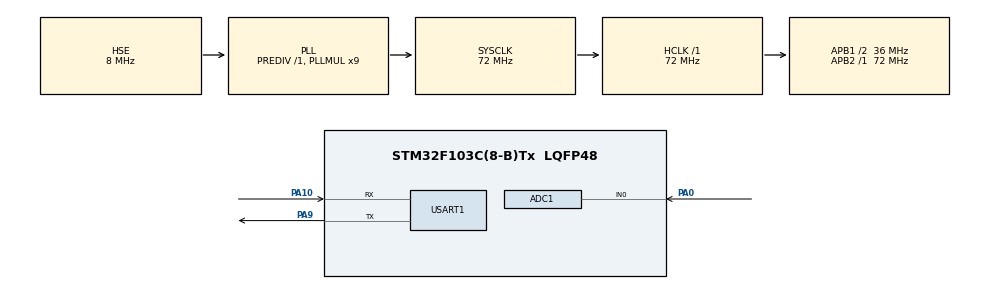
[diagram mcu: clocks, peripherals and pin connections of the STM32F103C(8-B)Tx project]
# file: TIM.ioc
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ADC1.Channel-0\#ChannelRegularConversion=ADC_CHANNEL_0
ADC1.NbrOfConversionFlag=1
ADC1.Rank-0\#ChannelRegularConversion=1
ADC1.SamplingTime-0\#ChannelRegularConversion=ADC_SAMPLETIME_1CYCLE_5
ADC1.master=1
Mcu.Family=STM32F1
Mcu.Name=STM32F103C(8-B)Tx
Mcu.Package=LQFP48
NVIC.PriorityGroup=NVIC_PRIORITYGROUP_4
NVIC.TIM4_IRQn=true\:0\:0\:false\:false\:true\:true\:true\:true
NVIC.USART1_IRQn=true\:0\:0\:false\:false\:true\:true\:true\:true
PA0-WKUP.Signal=ADCx_IN0
PA10.Mode=Asynchronous
PA10.Signal=USART1_RX
PA13.Mode=Serial_Wire
PA13.Signal=SYS_JTMS-SWDIO
PA14.Mode=Serial_Wire
PA14.Signal=SYS_JTCK-SWCLK
PA9.Mode=Asynchronous
PA9.Signal=USART1_TX
PD0-OSC_IN.Mode=HSE-External-Oscillator
PD0-OSC_IN.Signal=RCC_OSC_IN
PD1-OSC_OUT.Mode=HSE-External-Oscillator
PD1-OSC_OUT.Signal=RCC_OSC_OUT
ProjectManager.HeapSize=0x200
ProjectManager.StackSize=0x400
ProjectManager.TargetToolchain=CMake
RCC.ADCPresc=RCC_ADCPCLK2_DIV6
RCC.AHBFreq_Value=72000000
RCC.APB1CLKDivider=RCC_HCLK_DIV2
RCC.APB1Freq_Value=36000000
RCC.APB1TimFreq_Value=72000000
RCC.APB2Freq_Value=72000000
RCC.APB2TimFreq_Value=72000000
RCC.HCLKFreq_Value=72000000
RCC.PLLMUL=RCC_PLL_MUL9
RCC.PLLSourceVirtual=RCC_PLLSOURCE_HSE
RCC.SYSCLKFreq_VALUE=72000000
RCC.SYSCLKSource=RCC_SYSCLKSOURCE_PLLCLK
RCC.USBFreq_Value=72000000
SH.ADCx_IN0.0=ADC1_IN0,IN0
TIM4.Prescaler=7199
USART1.VirtualMode=VM_ASYNC
VP_TIM4_VS_ClockSourceINT.Mode=Internal
board=custom

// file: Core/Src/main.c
/* USER CODE BEGIN Header */
/**
  ******************************************************************************
  * @file           : main.c
  * @brief          : Main program body
  ******************************************************************************
  * @attention
  *
  * Copyright (c) 2026 STMicroelectronics.
  * All rights reserved.
  *
  * This software is licensed under terms that can be found in the LICENSE file
  * in the root directory of this software component.
  * If no LICENSE file comes with this software, it is provided AS-IS.
  *
  ******************************************************************************
  */
/* USER CODE END Header */
#include "main.h"

/* USER CODE BEGIN Includes */
#include <stdio.h>
#include <string.h>
/* USER CODE END Includes */

ADC_HandleTypeDef hadc1;

TIM_HandleTypeDef htim4;

UART_HandleTypeDef huart1;

/* USER CODE BEGIN PV */
/* TIM4 当前配置：Prescaler=7199 → 10 kHz，一个计数 = 0.1 ms */
uint32_t tim_total_01ms = 0U;   /* 累计的 0.1ms 计数 */
uint16_t tim_last_cnt   = 0U;   /* 上一次读到的 CNT，用于算增量 */
/* USER CODE END PV */

void SystemClock_Config(void);
static void MX_GPIO_Init(void);
static void MX_ADC1_Init(void);
static void MX_USART1_UART_Init(void);
static void MX_TIM4_Init(void);

/* USER CODE BEGIN 0 */
/**
  * @brief  把 TIM4 的计数增量累加进 tim_total_01ms
  * @note   CNT 是 16 位的，65535 之后回到 0。用无符号相减
  *         (uint16_t)(now - last) 天然就能跨过一次回绕算对增量，
  *         不需要手动判断"是不是变小了"。
  */
static void tim_update(void)
{
  uint16_t now   = (uint16_t)__HAL_TIM_GET_COUNTER(&htim4);
  uint16_t delta = (uint16_t)(now - tim_last_cnt);

  tim_last_cnt   = now;
  tim_total_01ms += delta;
}
/* USER CODE END 0 */

int main(void)
{

  /* MCU Configuration--------------------------------------------------------*/

  /* Reset of all peripherals, Initializes the Flash interface and the Systick. */
  HAL_Init();

  /* Configure the system clock */
  SystemClock_Config();

  /* Initialize all configured peripherals */
  MX_GPIO_Init();
  MX_ADC1_Init();
  MX_USART1_UART_Init();
  MX_TIM4_Init();
  /* USER CODE BEGIN 2 */
  static char msg[48];
  const char *boot = "TIM4 timer started\r\n";
  uint32_t last_print = 0U;

  HAL_TIM_Base_Start(&htim4);                    /* 启动 TIM4 开始计数 */
  tim_last_cnt   = (uint16_t)__HAL_TIM_GET_COUNTER(&htim4);
  tim_total_01ms = 0U;

  HAL_UART_Transmit(&huart1, (uint8_t *)boot, (uint16_t)strlen(boot), 200U);
  /* USER CODE END 2 */

  /* Infinite loop */
  /* USER CODE BEGIN WHILE */
  while (1)
  {
    uint16_t cnt;
    uint32_t ms;

    tim_update();                     /* 每圈都更新，快速转圈不会漏掉回绕 */

    if ((HAL_GetTick() - last_print) >= 100U)
    {
      last_print = HAL_GetTick();

      cnt = (uint16_t)__HAL_TIM_GET_COUNTER(&htim4);
      ms  = tim_total_01ms / 10U;     /* 0.1ms 计数换算成毫秒 */

      sprintf(msg, "CNT=%5u  elapsed=%lu ms\r\n", (unsigned)cnt, (unsigned long)ms);
      HAL_UART_Transmit(&huart1, (uint8_t *)msg, (uint16_t)strlen(msg), 200U);
    }
    /* USER CODE END WHILE */

  }
}

void SystemClock_Config(void)
{
  RCC_OscInitTypeDef RCC_OscInitStruct = {0};
  RCC_ClkInitTypeDef RCC_ClkInitStruct = {0};
  RCC_PeriphCLKInitTypeDef PeriphClkInit = {0};

  /** Initializes the RCC Oscillators according to the specified parameters
  * in the RCC_OscInitTypeDef structure.
  */
  RCC_OscInitStruct.OscillatorType = RCC_OSCILLATORTYPE_HSE;
  RCC_OscInitStruct.HSEState = RCC_HSE_ON;
  RCC_OscInitStruct.HSEPredivValue = RCC_HSE_PREDIV_DIV1;
  RCC_OscInitStruct.HSIState = RCC_HSI_ON;
  RCC_OscInitStruct.PLL.PLLState = RCC_PLL_ON;
  RCC_OscInitStruct.PLL.PLLSource = RCC_PLLSOURCE_HSE;
  RCC_OscInitStruct.PLL.PLLMUL = RCC_PLL_MUL9;
  if (HAL_RCC_OscConfig(&RCC_OscInitStruct) != HAL_OK)
  {
    Error_Handler();
  }

  /** Initializes the CPU, AHB and APB buses clocks
  */
  RCC_ClkInitStruct.ClockType = RCC_CLOCKTYPE_HCLK|RCC_CLOCKTYPE_SYSCLK
                              |RCC_CLOCKTYPE_PCLK1|RCC_CLOCKTYPE_PCLK2;
  RCC_ClkInitStruct.SYSCLKSource = RCC_SYSCLKSOURCE_PLLCLK;
  RCC_ClkInitStruct.AHBCLKDivider = RCC_SYSCLK_DIV1;
  RCC_ClkInitStruct.APB1CLKDivider = RCC_HCLK_DIV2;
  RCC_ClkInitStruct.APB2CLKDivider = RCC_HCLK_DIV1;

  if (HAL_RCC_ClockConfig(&RCC_ClkInitStruct, FLASH_LATENCY_2) != HAL_OK)
  {
    Error_Handler();
  }
  PeriphClkInit.PeriphClockSelection = RCC_PERIPHCLK_ADC;
  PeriphClkInit.AdcClockSelection = RCC_ADCPCLK2_DIV6;
  if (HAL_RCCEx_PeriphCLKConfig(&PeriphClkInit) != HAL_OK)
  {
    Error_Handler();
  }
}

static void MX_ADC1_Init(void)
{

  ADC_ChannelConfTypeDef sConfig = {0};

  /** Common config
  */
  hadc1.Instance = ADC1;
  hadc1.Init.ScanConvMode = ADC_SCAN_DISABLE;
  hadc1.Init.ContinuousConvMode = DISABLE;
  hadc1.Init.DiscontinuousConvMode = DISABLE;
  hadc1.Init.ExternalTrigConv = ADC_SOFTWARE_START;
  hadc1.Init.DataAlign = ADC_DATAALIGN_RIGHT;
  hadc1.Init.NbrOfConversion = 1;
  if (HAL_ADC_Init(&hadc1) != HAL_OK)
  {
    Error_Handler();
  }

  /** Configure Regular Channel
  */
  sConfig.Channel = ADC_CHANNEL_0;
  sConfig.Rank = ADC_REGULAR_RANK_1;
  sConfig.SamplingTime = ADC_SAMPLETIME_1CYCLE_5;
  if (HAL_ADC_ConfigChannel(&hadc1, &sConfig) != HAL_OK)
  {
    Error_Handler();
  }

}

static void MX_TIM4_Init(void)
{

  TIM_ClockConfigTypeDef sClockSourceConfig = {0};
  TIM_MasterConfigTypeDef sMasterConfig = {0};

  htim4.Instance = TIM4;
  htim4.Init.Prescaler = 7199;
  htim4.Init.CounterMode = TIM_COUNTERMODE_UP;
  htim4.Init.Period = 65535;
  htim4.Init.ClockDivision = TIM_CLOCKDIVISION_DIV1;
  htim4.Init.AutoReloadPreload = TIM_AUTORELOAD_PRELOAD_DISABLE;
  if (HAL_TIM_Base_Init(&htim4) != HAL_OK)
  {
    Error_Handler();
  }
  sClockSourceConfig.ClockSource = TIM_CLOCKSOURCE_INTERNAL;
  if (HAL_TIM_ConfigClockSource(&htim4, &sClockSourceConfig) != HAL_OK)
  {
    Error_Handler();
  }
  sMasterConfig.MasterOutputTrigger = TIM_TRGO_RESET;
  sMasterConfig.MasterSlaveMode = TIM_MASTERSLAVEMODE_DISABLE;
  if (HAL_TIMEx_MasterConfigSynchronization(&htim4, &sMasterConfig) != HAL_OK)
  {
    Error_Handler();
  }

}

static void MX_USART1_UART_Init(void)
{

  huart1.Instance = USART1;
  huart1.Init.BaudRate = 115200;
  huart1.Init.WordLength = UART_WORDLENGTH_8B;
  huart1.Init.StopBits = UART_STOPBITS_1;
  huart1.Init.Parity = UART_PARITY_NONE;
  huart1.Init.Mode = UART_MODE_TX_RX;
  huart1.Init.HwFlowCtl = UART_HWCONTROL_NONE;
  huart1.Init.OverSampling = UART_OVERSAMPLING_16;
  if (HAL_UART_Init(&huart1) != HAL_OK)
  {
    Error_Handler();
  }

}

static void MX_GPIO_Init(void)
{

  /* GPIO Ports Clock Enable */
  __HAL_RCC_GPIOD_CLK_ENABLE();
  __HAL_RCC_GPIOA_CLK_ENABLE();

}

void Error_Handler(void)
{
  __disable_irq();
  while (1)
  {
  }
}
